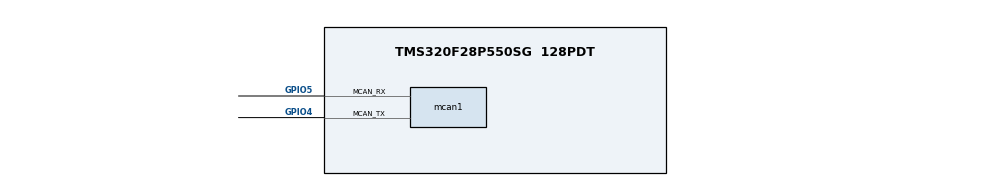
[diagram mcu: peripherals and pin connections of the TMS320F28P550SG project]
/**
 * AI AGENTS: Do not edit this file directly. There is no validation or error feedback when
 * editing manually — mistakes will be silent until the file is loaded in SysConfig.
 * Use the SysConfig MCP server instead to make changes with immediate error reporting.
 *
 * These arguments were used when this file was generated. They will be automatically applied on subsequent loads
 * via the GUI or CLI. Run CLI with '--help' for additional information on how to override these arguments.
 * @cliArgs --device "F28P55x" --part "F28P55x_128PDT" --package "128PDT" --context "system" --product "C2000WARE@26.01.00.00"
 * @v2CliArgs --device "TMS320F28P550SG" --package "128PDT" --variant "TMS320F28P550SG9" --context "system" --product "C2000WARE@26.01.00.00"
 * @versions {"tool":"1.28.0+4696"}
 */

/**
 * Import the modules used in this configuration.
 */
const device_support = scripting.addModule("/driverlib/device_support.js");
const epwm           = scripting.addModule("/driverlib/epwm.js", {}, false);
const epwm1          = epwm.addInstance();
const epwm2          = epwm.addInstance();
const mcan           = scripting.addModule("/driverlib/mcan.js", {}, false);
const mcan1          = mcan.addInstance();
const spi            = scripting.addModule("/driverlib/spi.js", {}, false);
const spi1           = spi.addInstance();

/**
 * Write custom configuration values to the imported modules.
 */
const divider4       = system.clockTree["MCANACLKDIV"];
divider4.divideValue = 3;

epwm1.$name = "myEPWM1";

epwm2.$name = "myEPWM2";

mcan1.$name                    = "myMCANA";
mcan1.dataRatePrescalar        = 7;
mcan1.useCalcStartingAddress   = true;
mcan1.txBufNum                 = 32;
mcan1.rxFIFO0size              = 16;
mcan1.autoWkupEnable           = true;
mcan1.enableInterrupt          = true;
mcan1.interruptFlags           = ["MCAN_INTR_MASK_ALL"];
mcan1.interruptLine            = ["MCAN_INTR_LINE_NUM_0"];
mcan1.registerInterruptLine0   = true;
mcan1.fdMode                   = false;
mcan1.brsEnable                = false;
mcan1.loopbackMode             = false;
mcan1.interruptLine0Flag       = ["MCAN_INTR_MASK_ALL"];
mcan1.mcan.$assign             = "MCANA";
mcan1.mcan.mcan_rxPin.$assign  = "GPIO5";
mcan1.mcan.mcan_txPin.$assign  = "GPIO4";
mcan1.mcanInt0.enableInterrupt = true;

spi1.$name          = "mySPIB";
spi1.picoQual.$name = "myGPIOQUAL0";
spi1.pociQual.$name = "myGPIOQUAL1";
spi1.clkQual.$name  = "myGPIOQUAL2";
spi1.pteQual.$name  = "myGPIOQUAL3";

/**
 * Pinmux solution for unlocked pins/peripherals. This ensures that minor changes to the automatic solver in a future
 * version of the tool will not impact the pinmux you originally saw.  These lines can be completely deleted in order to
 * re-solve from scratch.
 */
epwm1.epwm.$suggestSolution           = "EPWM2";
epwm1.epwm.epwm_aPin.$suggestSolution = "A10, B1, C10, GPIO230";
epwm1.epwm.epwm_bPin.$suggestSolution = "A6, D14, E14, GPIO228";
epwm2.epwm.$suggestSolution           = "EPWM1";
epwm2.epwm.epwm_aPin.$suggestSolution = "GPIO0";
epwm2.epwm.epwm_bPin.$suggestSolution = "B2, C6, E12, GPIO226";
spi1.spi.$suggestSolution             = "SPIA";
spi1.spi.spi_picoPin.$suggestSolution = "A2, B6, C9, PGA1_INP, GPIO224";
spi1.spi.spi_pociPin.$suggestSolution = "A19, B19, C19, GPIO13";
spi1.spi.spi_clkPin.$suggestSolution  = "A20, B20, C20, GPIO12";
spi1.spi.spi_ptePin.$suggestSolution  = "A24, D0, E0, GPIO11";
